# MIMXRT1021 register map
Vendor: nxp.com; File version: 1.0
CPU: CM7 r0p1, little endian, MPU, FPU, VTOR, 4 interrupt priority bits
Registers are 32-bit, read-write, reset 0x0 unless marked. A register's access mark holds for its fields unless they carry their own. Offsets are from the block's base; [hi:lo] are bit positions; {n}, {i} and the like mark numbered series; 'fields as' and 'values as' point back to an identical list.

## IOMUXC_SNVS_GPR — IOMUXC
Base 0x400A4000; register names take the prefix IOMUXC_SNVS_GPR_
{0x0+4i} GPR{i} ro (i=0..2) — GPR{i} General Purpose Register
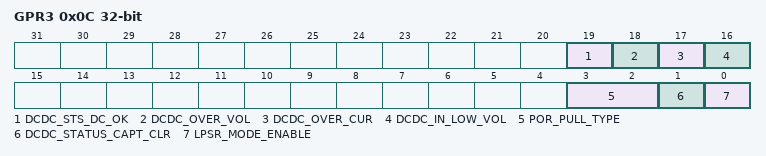
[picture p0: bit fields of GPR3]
0x0C GPR3 — GPR3 General Purpose Register
  [19] DCDC_STS_DC_OK ro — DCDC status OK
    0=DCDC is ramping up and not ready; 1=DCDC is ready
  [18] DCDC_OVER_VOL ro — DCDC output over voltage alert
    0=No over voltage detected; 1=Over voltage detected
  [17] DCDC_OVER_CUR ro — DCDC output over current alert
    0=No over current detected; 1=Over current detected
  [16] DCDC_IN_LOW_VOL ro — DCDC_IN low voltage detect.
    0=DCDC_IN is ok; 1=DCDC_IN is too low
  [3:2] POR_PULL_TYPE — POR_B pad control
    0=100 Ohm pull up enabled for POR_B always; 1=Disable pull in SNVS mode, 100 Ohm pull up enabled otherwise; 2=Disable pull of POR_B always; 3=100 Ohm pull down enabled in SNVS mode, 100 Ohm pull up enabled otherwise
  [1] DCDC_STATUS_CAPT_CLR — DCDC captured status clear
  [0] LPSR_MODE_ENABLE — Set to enable LPSR mode.
    0=SNVS domain will reset when system reset happens; 1=SNVS domain will only reset with SNVS POR

## IOMUXC_SNVS
Base 0x400A8000; register names take the prefix IOMUXC_SNVS_
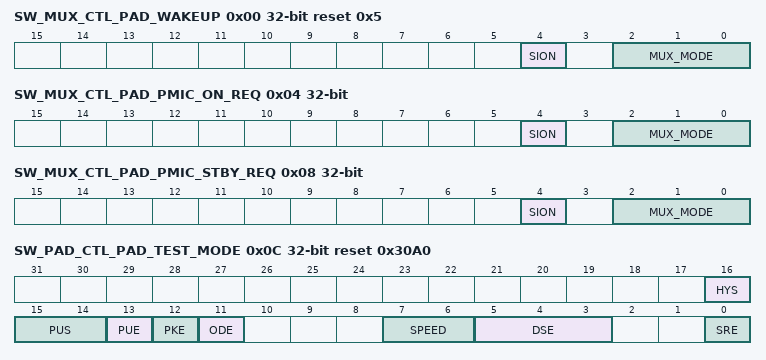
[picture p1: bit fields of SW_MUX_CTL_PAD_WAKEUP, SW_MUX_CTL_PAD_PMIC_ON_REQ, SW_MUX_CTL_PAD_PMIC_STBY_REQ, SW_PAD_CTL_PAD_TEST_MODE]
0x00 SW_MUX_CTL_PAD_WAKEUP reset 0x5 — SW_MUX_CTL_PAD_WAKEUP SW MUX Control Register
  [4] SION — Software Input On Field.
    0=DISABLED (Input Path is determined by functionality); 1=ENABLED (Force input path of pad WAKEUP)
  [2:0] MUX_MODE — MUX Mode Select Field.
    5=ALT5 (Select mux mode: ALT5 mux port: GPIO5_IO00 of instance: gpio5); 7=ALT7 (Select mux mode: ALT7 mux port: NMI_GLUE_NMI of instance: nmi_glue)
0x04 SW_MUX_CTL_PAD_PMIC_ON_REQ — SW_MUX_CTL_PAD_PMIC_ON_REQ SW MUX Control Register
  [4] SION — Software Input On Field.
    0=DISABLED (Input Path is determined by functionality); 1=ENABLED (Force input path of pad PMIC_ON_REQ)
  [2:0] MUX_MODE — MUX Mode Select Field.
    0=ALT0 (Select mux mode: ALT0 mux port: SNVS_LP_PMIC_ON_REQ of instance: snvs_lp); 5=ALT5 (Select mux mode: ALT5 mux port: GPIO5_IO01 of instance: gpio5)
0x08 SW_MUX_CTL_PAD_PMIC_STBY_REQ — SW_MUX_CTL_PAD_PMIC_STBY_REQ SW MUX Control Register
  [4] SION — Software Input On Field.
    0=DISABLED (Input Path is determined by functionality); 1=ENABLED (Force input path of pad PMIC_STBY_REQ)
  [2:0] MUX_MODE — MUX Mode Select Field.
    0=ALT0 (Select mux mode: ALT0 mux port: CCM_PMIC_VSTBY_REQ of instance: ccm); 5=ALT5 (Select mux mode: ALT5 mux port: GPIO5_IO02 of instance: gpio5)
0x0C SW_PAD_CTL_PAD_TEST_MODE reset 0x30A0 — SW_PAD_CTL_PAD_TEST_MODE SW PAD Control Register
  [16] HYS — Hyst. Enable Field
    0=HYS_0_Hysteresis_Disabled (Hysteresis Disabled); 1=HYS_1_Hysteresis_Enabled (Hysteresis Enabled)
  [15:14] PUS — Pull Up / Down Config. Field
    0=PUS_0_100K_Ohm_Pull_Down (100K Ohm Pull Down); 1=PUS_1_47K_Ohm_Pull_Up (47K Ohm Pull Up); 2=PUS_2_100K_Ohm_Pull_Up (100K Ohm Pull Up); 3=PUS_3_22K_Ohm_Pull_Up (22K Ohm Pull Up)
  [13] PUE — Pull / Keep Select Field
    0=PUE_0_Keeper (Keeper); 1=PUE_1_Pull (Pull)
  [12] PKE — Pull / Keep Enable Field
    0=PKE_0_Pull_Keeper_Disabled (Pull/Keeper Disabled); 1=PKE_1_Pull_Keeper_Enabled (Pull/Keeper Enabled)
  [11] ODE — Open Drain Enable Field
    0=ODE_0_Open_Drain_Disabled (Open Drain Disabled); 1=ODE_1_Open_Drain_Enabled (Open Drain Enabled)
  [7:6] SPEED ro
    2=SPEED (medium(100MHz))
  [5:3] DSE — Drive Strength Field
    0=DSE_0_output_driver_disabled_ (output driver disabled;); 1=DSE_1_R0_150_Ohm___3_3V__260_Ohm_1_8V (R0(150 Ohm @ 3.3V, 260 Ohm@1.8V)); {v}=DSE_{v}_R0_{v} (R0/{v}) (v=2..7)
  [0] SRE — Slew Rate Field
    0=SRE_0_Slow_Slew_Rate (Slow Slew Rate); 1=SRE_1_Fast_Slew_Rate (Fast Slew Rate)
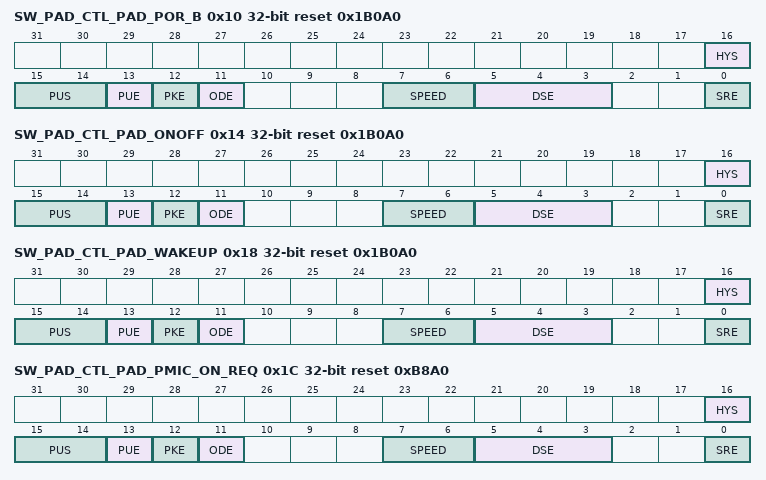
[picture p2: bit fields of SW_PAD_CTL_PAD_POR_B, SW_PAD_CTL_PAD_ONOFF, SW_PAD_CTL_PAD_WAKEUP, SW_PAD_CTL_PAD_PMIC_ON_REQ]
0x10 SW_PAD_CTL_PAD_POR_B reset 0x1B0A0 — SW_PAD_CTL_PAD_POR_B SW PAD Control Register
  fields as SW_PAD_CTL_PAD_TEST_MODE
0x14 SW_PAD_CTL_PAD_ONOFF reset 0x1B0A0 — SW_PAD_CTL_PAD_ONOFF SW PAD Control Register
  fields as SW_PAD_CTL_PAD_TEST_MODE
0x18 SW_PAD_CTL_PAD_WAKEUP reset 0x1B0A0 — SW_PAD_CTL_PAD_WAKEUP SW PAD Control Register
  fields as SW_PAD_CTL_PAD_TEST_MODE
0x1C SW_PAD_CTL_PAD_PMIC_ON_REQ reset 0xB8A0 — SW_PAD_CTL_PAD_PMIC_ON_REQ SW PAD Control Register
  fields as SW_PAD_CTL_PAD_TEST_MODE
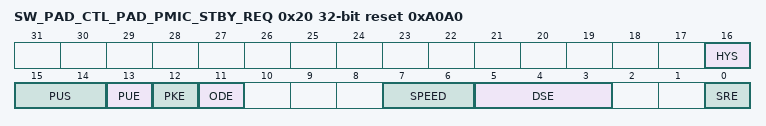
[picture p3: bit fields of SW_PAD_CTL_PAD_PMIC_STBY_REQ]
0x20 SW_PAD_CTL_PAD_PMIC_STBY_REQ reset 0xA0A0 — SW_PAD_CTL_PAD_PMIC_STBY_REQ SW PAD Control Register
  fields as SW_PAD_CTL_PAD_TEST_MODE
